# RL6955_IP_SVD register map
Vendor: Realtek
Registers are 32-bit, read-write, reset 0x0 unless marked. A register's access mark holds for its fields unless they carry their own. Offsets are from the block's base; [hi:lo] are bit positions; {n}, {i} and the like mark numbered series.

## CTC_REG
Base 0x4100B000
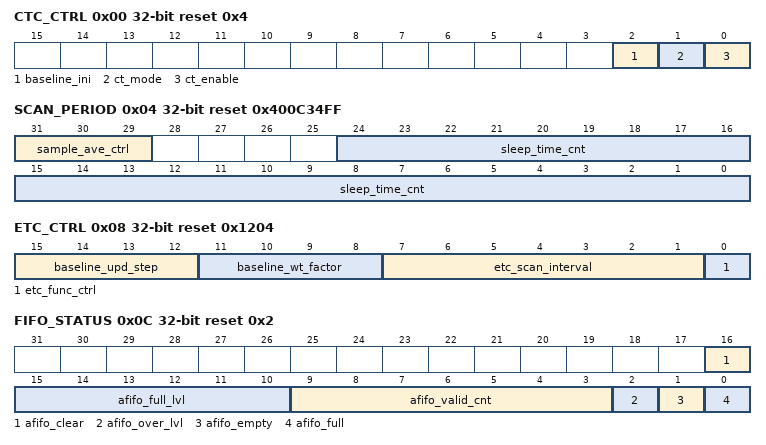
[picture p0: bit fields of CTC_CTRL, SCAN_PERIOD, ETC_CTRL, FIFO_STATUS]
0x00 CTC_CTRL reset 0x4 — Captouch Control Register
  [2] baseline_ini — 1: Baseline initial function enable, HW will clear this bit to "0" after baseline initial
  [1] ct_mode — 0: Comparator mode 1: SAR ADC mode
  [0] ct_enable — 0: CTC disable 1: CTC enable
0x04 SCAN_PERIOD reset 0x400C34FF — Scan Parameters Register
  [31:29] sample_ave_ctrl — ADC sampled number for average function (SAR ADC mode) average number=2^(sample_ave_ctrl+1)
  [24:0] sleep_time_cnt — clk40M When this register is set to 0, HW will scan continuously and have no sleep time.
0x08 ETC_CTRL reset 0x1204 — Environment Tracking Control Register
  [15:12] baseline_upd_step — Baseline update step for all channel
  [11:8] baseline_wt_factor — Baseline update weight factor (ETC_factor_th) for all channel ETC_factor_th=2^baseline_wt_factor
  [7:1] etc_scan_interval — ETC update interval between scan period (sleep time) for all channel Interval=(etc_scan_interval+1)*scan_period
  [0] etc_func_ctrl — Environmental cap tracking calibration function 0: Disable 1: Enable
0x0C FIFO_STATUS access per field reset 0x2
  [16] afifo_clear wo — clear the FIFO data
  [15:10] afifo_full_lvl rw — user define the full level for afifo, the valid value is from 0 to 63
  [9:3] afifo_valid_cnt ro — FIFO valid cnt(push unit number which can be read)
  [2] afifo_over_lvl ro — 0: FIFO not over level 1: FIFO over level
  [1] afifo_empty ro — 0: FIFO not empty 1: FIFO empty
  [0] afifo_full ro — 0: FIFO not oveflow (not full) 1: FIFO overflow(full)
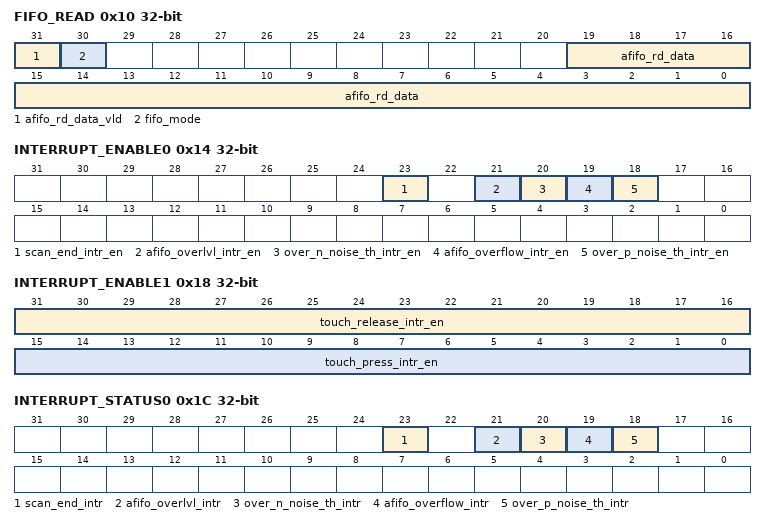
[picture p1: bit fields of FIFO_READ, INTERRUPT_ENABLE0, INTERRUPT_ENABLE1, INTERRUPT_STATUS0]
0x10 FIFO_READ access per field
  [31] afifo_rd_data_vld ro — Read data from raw code FIFO valid
  [30] fifo_mode rw — Controls the write type of FIFO data 1:filtered data 0: raw data
  [19:0] afifo_rd_data ro — Read data from FIFO [15:0] : data [19:16] : channel number
0x14 INTERRUPT_ENABLE0 — Interrupt Enable Register
  [23] scan_end_intr_en — sample scan finish enable
  [21] afifo_overlvl_intr_en — Raw code FIFO over level enable
  [20] over_n_noise_th_intr_en — Negative noise threshold overflow enable
  [19] afifo_overflow_intr_en — Raw code FIFO overflow enable
  [18] over_p_noise_th_intr_en — Positive noise threshold overflow enable
0x18 INTERRUPT_ENABLE1 — Interrupt Enable Register
  [31:16] touch_release_intr_en — Channelx single touch release enable, x is 0~8
  [15:0] touch_press_intr_en — Channelx single touch press enable, x is 0~8
0x1C INTERRUPT_STATUS0 ro — interrupt status register
  [23] scan_end_intr — sample scan finish interrupt
  [21] afifo_overlvl_intr — Raw code FIFO over level interrupt
  [20] over_n_noise_th_intr — Negative noise threshold overflow interrupt
  [19] afifo_overflow_intr — Raw code FIFO overflow interrupt
  [18] over_p_noise_th_intr — Positive noise threshold overflow interrupt
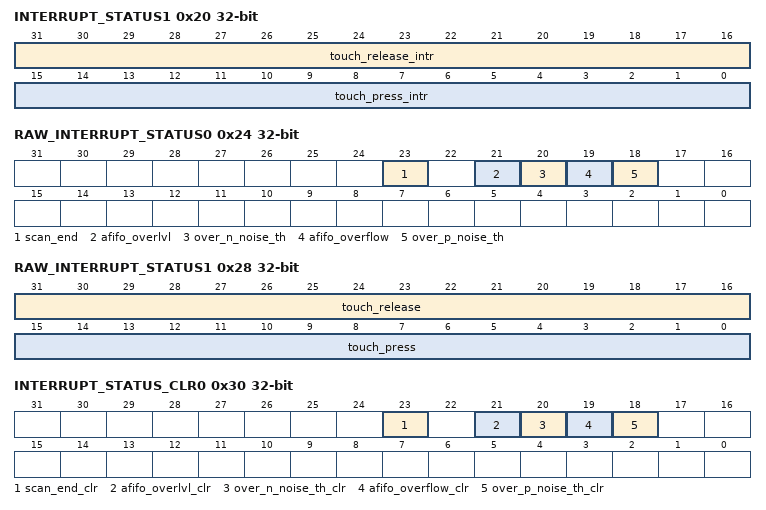
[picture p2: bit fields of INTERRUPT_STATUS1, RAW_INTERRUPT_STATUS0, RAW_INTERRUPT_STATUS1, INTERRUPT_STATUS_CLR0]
0x20 INTERRUPT_STATUS1 ro — interrupt status register
  [31:16] touch_release_intr — Channelx single touch release interrupt, x is 0~8
  [15:0] touch_press_intr — Channelx single touch press interrupt, x is 0~8
0x24 RAW_INTERRUPT_STATUS0 ro — Raw Interrupt Status Register
  [23] scan_end — sample scan finish raw interrupt
  [21] afifo_overlvl — Raw code FIFO over level raw interrupt
  [20] over_n_noise_th — Negative noise threshold overflow raw interrupt
  [19] afifo_overflow — Raw code FIFO overflow raw interrupt
  [18] over_p_noise_th — Positive noise threshold overflow raw interrupt
0x28 RAW_INTERRUPT_STATUS1 ro — Raw Interrupt Status Register
  [31:16] touch_release — Channelx single touch release raw interrupt, x is 0~8
  [15:0] touch_press — Channelx single touch press raw interrupt, x is 0~8
0x2C INTERRUPT_ALL_CLR — Interrupt All Clear Register
  [0] intr_all_clr — Write "1" to this register to clear the combined interrupts, all individual interrupts, interrupt status register and raw interrupt status register.
0x30 INTERRUPT_STATUS_CLR0 — Interrupt Clear Register
  [23] scan_end_clr — sample scan finish raw interrupt and related register
  [21] afifo_overlvl_clr — Clear raw code FIFO over level raw interrupt and related register
  [20] over_n_noise_th_clr — Clear negative noise threshold overflow interrupt and related register
  [19] afifo_overflow_clr — Clear raw code FIFO overflow interrupt and related register
  [18] over_p_noise_th_clr — Clear positive noise threshold overflow interrupt and related register
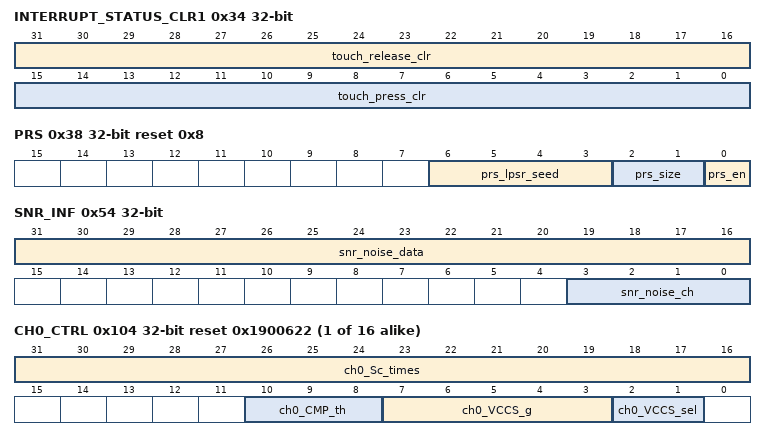
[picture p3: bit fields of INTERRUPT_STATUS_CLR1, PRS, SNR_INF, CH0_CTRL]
0x34 INTERRUPT_STATUS_CLR1 — Interrupt Clear Register
  [31:16] touch_release_clr — Clear channelx single touch release interrupt and related register
  [15:0] touch_press_clr — Clear channelx single touch press interrupt and related register
0x38 PRS reset 0x8 — PRS Select Register
  [6:3] prs_lpsr_seed — lpsr seed. it can't be 0.
  [2:1] prs_size — 00: lpsr width is 2 01: lpsr width is 3 10: lpsr width is 4
  [0] prs_en — PRS enable
0x40 DEBUG_SEL — Debug Select Register
  [2:0] dbg_sel — Debug information selection 0: dbg_clkrst 1: dbg_apbslv 2: dbg_ctrl 3: dbg_decision 4: dbg_adc_arb Others: dbg_clkrst
0x44 DEBUG_PORT ro — Debug Register
  [31:0] dbg_port — Debug port output value,depend on dbg_sel value
0x48 ECO_USE0
  [31:0] eco_use0 — For ECO use
0x4C ECO_USE1
  [31:0] eco_use1 — For ECO use
0x50 CTC_COMP_VERSION reset 0x20250310 — Version Register
  [31:0] comp_version — CTC version number
0x54 SNR_INF access per field — Signal Noise Ratio Register
  [31:16] snr_noise_data ro — Noise peak to peak signal raw data for SNR monitor
  [3:0] snr_noise_ch rw — Specify which channel you want to read the snr_noise_data data
{0x104+0x1C*i} CH{i}_CTRL reset 0x1900622 (i=0..15) — Channel {i} Control Register
  [31:16] ch{i}_Sc_times — 0~65536 times, Only used in SAR ADC mode.When the counter reaches the set value, the switching capacitor action is stopped immediately and the voltage sampling is performed after the ADC is ready.The actual value will be one more due to the counter.
  [10:8] ch{i}_CMP_th — 0.5V~0.7V,it has 8 data gear selections. Only used in comparator mode, triggered when the voltage reaches the comparator threshold
  [7:3] ch{i}_VCCS_g — Compensate current source gear selection. (1/180K) *(50uA+5uA*<4:0>) /10uA
  [2:1] ch{i}_VCCS_sel — ch{i}_VCCS_sel: 00: SEL_TOUCH_CUR_0V2I_1IBHN, EN_TOUCHCUR_CALI disable ,use default (off mode) 01: SEL_TOUCH_CUR_0V2I_1IBHN = 0; EN_TOUCHCUR_CALI = 0 (normal mode) 10: SEL_TOUCH_CUR_0V2I_1IBHN = 0; EN_TOUCHCUR_CALI = 1 (calibration mode) 11: SEL_TOUCH_CUR_0V2I_1IBHN = 1; EN_TOUCHCUR_CALI = 0 (debug mode)
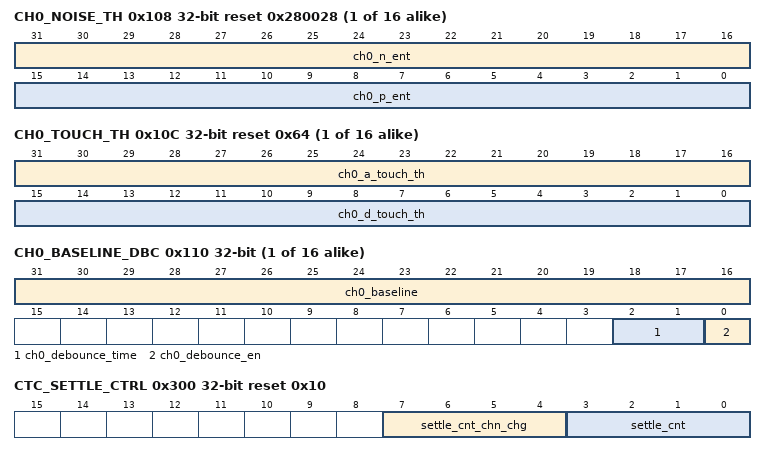
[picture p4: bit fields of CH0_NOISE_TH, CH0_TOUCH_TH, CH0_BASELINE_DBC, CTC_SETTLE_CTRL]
{0x108+0x1C*i} CH{i}_NOISE_TH reset 0x280028 (i=0..15) — Channel {i} Noise Threshold Register
  [31:16] ch{i}_n_ent — The environmental negative noise threshold: the negative maximum capacitance change of raw data that is still considered an environment change.
  [15:0] ch{i}_p_ent — The environmental positive noise threshold: the positive maximum capacitance change of raw data that is still considered an environment change.
{0x10C+0x1C*i} CH{i}_TOUCH_TH reset 0x64 (i=0..15) — Channel {i} Threshold Register
  [31:16] ch{i}_a_touch_th — Absolute threshold data of touch judgement for channel {i}. It can be updated by HW when baseline initial function or ETC function enabled, a_touch_th=baseline-d_touch_th, manual tuning when ETC disabled, (0x0~0xFFF). Recommended data=80%*signal
  [15:0] ch{i}_d_touch_th — Difference threshold data of touch judgement for channel {i}. It needs to be configured during development, (0x0~0xFFF) (0~4095). Init number=0x64 Recommend data=80%*(signal-baseline)
{0x110+0x1C*i} CH{i}_BASELINE_DBC (i=0..15) — Channel {i}
  [31:16] ch{i}_baseline — Digital baseline data of channel {i}. Init number=0x0 It can be initialed by HW when baseline initial function enabled, and can be updated automatically by HW when ETC function enabled. It could be configured by manual tuning.
  [2:1] ch{i}_debounce_time — 2'b00: 2 times 2'b01: 3 times 2'b10: 4 times 2'b11: 5 times
  [0] ch{i}_debounce_en — 0: Disable 1: Enable
0x300 CTC_SETTLE_CTRL reset 0x10 — Captouch Settle Control Register
  [7:4] settle_cnt_chn_chg — settle count for sample data from chn switch, the unit is sample clock. 0 means no need to settle
  [3:0] settle_cnt — settle count for sample data from ADC to captouch, the unit is sample clock. 0 means no need to settle
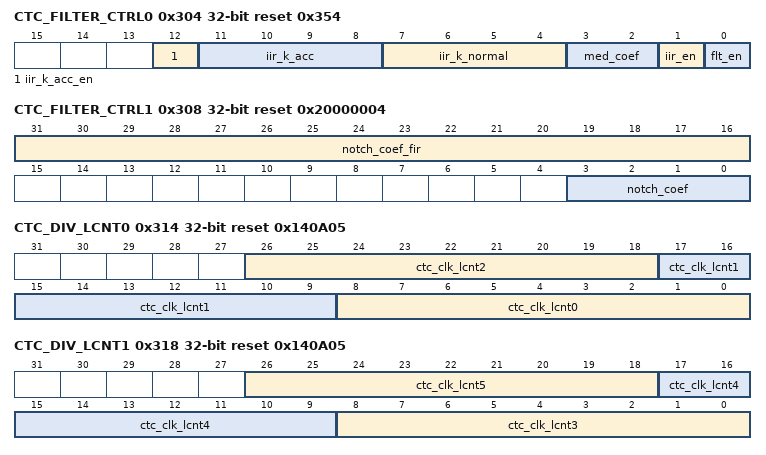
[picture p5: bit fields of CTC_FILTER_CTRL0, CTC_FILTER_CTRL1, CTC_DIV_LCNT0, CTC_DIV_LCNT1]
0x304 CTC_FILTER_CTRL0 reset 0x354 — Captouch Filter Control0 Register
  [12] iir_k_acc_en — enable accelerated touch response.
  [11:8] iir_k_acc — iir filter coef. the range is 0~11.
  [7:4] iir_k_normal — iir filter coef
  [3:2] med_coef — Median filter coefficient,for raw data 00:disable 01:coef is 3 10:coef is 5 11:coef is 7
  [1] iir_en — Enable ctc iir function,for raw data
  [0] flt_en — Enable ctc filter function(global),for raw data
0x308 CTC_FILTER_CTRL1 reset 0x20000004 — Captouch Filter Control1 Register
  [31:16] notch_coef_fir — The coefficient of the sliding filter.The divisor.
  [3:0] notch_coef — The coefficient of the sliding filter.The window width factor 0,1: disable 2-8: useful
0x30C CTC_NOISE_CNT reset 0xC8 — Captouch Noise Cnt Register
  [11:0] noise_cnt — This parameter is used to set the refresh time of the noise data.The counter is updated after the data has been processed to the last channel
0x310 CTC_DIV_HCNT reset 0x4 — Captouch Div Hcnt Control Register
  [8:0] ctc_clk_hcnt — This field defines sample clock driver high level of chn. high level = (ctc_clk_hcnt +1)* ip_clk period
0x314 CTC_DIV_LCNT0 reset 0x140A05 — Captouch Div Lcnt Control Register
  [26:18] ctc_clk_lcnt2 — This field defines sample clock driver lower level of chn. lower level = ctc_clk_lcnt2 * ip_clk period
  [17:9] ctc_clk_lcnt1 — This field defines sample clock driver lower level of chn. lower level = ctc_clk_lcnt1 * ip_clk period
  [8:0] ctc_clk_lcnt0 — This field defines sample clock driver lower level of chn lower level = ctc_clk_lcnt0 * ip_clk period
0x318 CTC_DIV_LCNT1 reset 0x140A05 — Captouch Div Lcnt Control Register
  [26:18] ctc_clk_lcnt5 — This field defines sample clock driver lower level of chn. lower level = ctc_clk_lcnt2 * ip_clk period
  [17:9] ctc_clk_lcnt4 — This field defines sample clock driver lower level of chn. lower level = ctc_clk_lcnt1 * ip_clk period
  [8:0] ctc_clk_lcnt3 — This field defines sample clock driver lower level of chn lower level = ctc_clk_lcnt0 * ip_clk period
0x31C CTC_DIV_LCNT2 reset 0x5 — Captouch Div Lcnt Control Register
  [8:0] ctc_clk_lcnt6 — This field defines sample clock driver lower level of chn lower level = ctc_clk_lcnt0 * ip_clk period
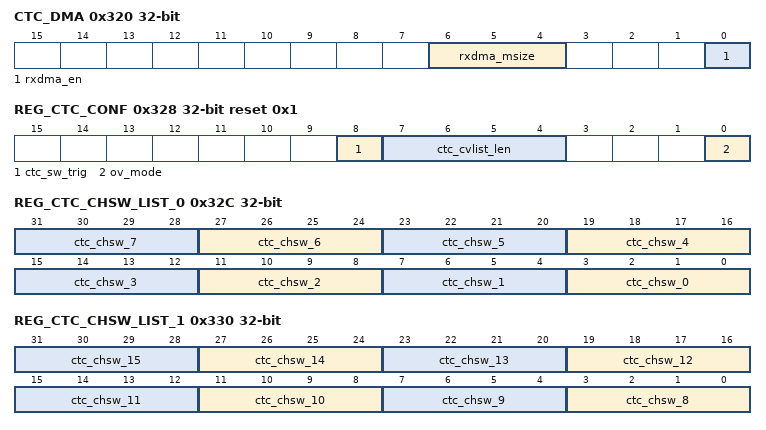
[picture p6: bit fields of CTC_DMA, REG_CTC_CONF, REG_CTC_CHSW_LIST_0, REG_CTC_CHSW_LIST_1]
0x320 CTC_DMA — Captouch DMA Register
  [6:4] rxdma_msize — ctc rxdma burst size. When fifo reach certain entry depth , controller will req dma operation. 0: 1 entry 1: 4 2: 8 N: 2**(N+1) Note: this setting must be same with GDMA burst len , or fifo will underflow or overflow.
  [0] rxdma_en — 1:enable ctc rxdma Note: ctc dma interface must used GDMA as flow control , IP flow control is not support .
0x324 REG_CTC_CM_CNT reset 0x18F
  [11:0] ctc_cm_cnt — This field controls the time it takes for the power supply (Vd) to charge the capacitor Cm when each channel of Captouch starts working. Charging Time = (ctc_cm_cnt +1) * ip_clk_period.
0x328 REG_CTC_CONF reset 0x1 — Captouch Configuration Register
  [8] ctc_sw_trig — This bit controls the ctc module to do a conversion. Every time this bit is set to 1, ctc module would switch to a new channel and do one conversion. Therefore, this bit could be used as a start-convert event which is controlled by software. Every time a conversion is done, software MUST clear this bit manually. The interval between clearing and restart this bit must exceed one sample clock period. 0: disable the analog module and analog mux. 1: enable the analog module and analog mux. And then start a new channel conversion.
  [7:4] ctc_cvlist_len — This field defines the number of items in the ctc conversion channel list.
  [0] ov_mode — sample mode 0-All sample conversions done in staggered sequence 1-All sample conversions done in regular sequence
0x32C REG_CTC_CHSW_LIST_0 — Captouch Channel Switch List 0 Register
  [4n+3:4n] ctc_chsw_{n} (n=0..7) — This field defines the number {n} channel to do a conversion when a conversion event takes place.
0x330 REG_CTC_CHSW_LIST_1 — Captouch Channel Switch List 1 Register
  [4n-29:4n-32] ctc_chsw_{n} (n=8..15) — This field defines the number {n} channel to do a conversion when a conversion event takes place.
0x334 REG_CTC_DUMMY reset 0xF0 — Captouch Dummy Register
